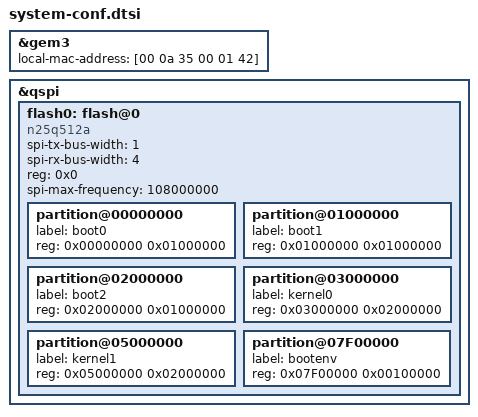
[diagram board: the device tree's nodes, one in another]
&gem3 {
    local-mac-address = [00 0a 35 00 01 42];
};

&qspi {
    #address-cells = <1>;
    #size-cells = <0>;
    flash0: flash@0 {
        compatible = "n25q512a","micron,m25p80";
        spi-tx-bus-width=<1>;
        spi-rx-bus-width=<4>;
        reg = <0x0>;
        #address-cells = <1>;
        #size-cells = <1>;
        spi-max-frequency = <108000000>;
        partition@00000000 {
            label = "boot0";
            reg = <0x00000000 0x01000000>;
        };
        partition@01000000 {
            label = "boot1";
            reg = <0x01000000 0x01000000>;
        };
        partition@02000000 {
            label = "boot2";
            reg = <0x02000000 0x01000000>;
        };
        partition@03000000 {
            label = "kernel0";
            reg = <0x03000000 0x02000000>;
        };
        partition@05000000 {
            label = "kernel1";
            reg = <0x05000000 0x02000000>;
        };
        /* Free space between 0x07000000 and 0x07F00000 */
        partition@07F00000 {
            label = "bootenv";
            reg = <0x07F00000 0x00100000>;
        };
    };
};

